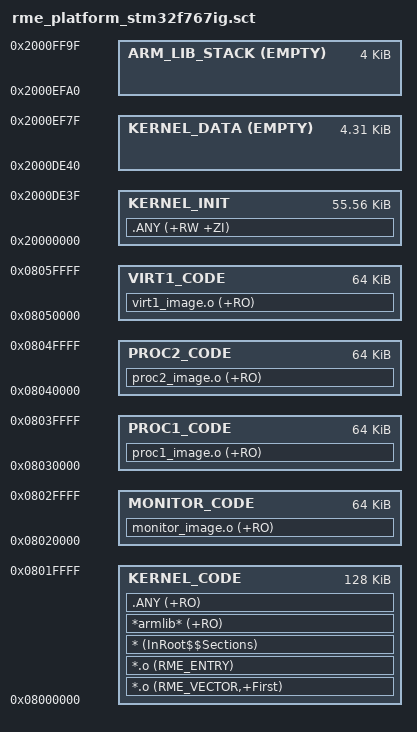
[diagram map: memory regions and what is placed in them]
;******************************************************************************
;Filename    : rme_platform_stm32f767ig.sct
;Author      : The RVM project generator.
;Date        : 26/09/2024 10:23:17
;Licence     : Unlicense; see COPYING for details.
;Description : The scatter file for ARMv7-M layout. This file is intended
;              to be used with STM32F767IG.
;******************************************************************************

;Kernel ***********************************************************************
KERNEL 0x8000000 0x20000
{
    ;Kernel code segment
    KERNEL_CODE 0x8000000 0x20000
    {
        ;The vector table
        *.o                            (RME_VECTOR,+First)
        ;The entry
        *.o                            (RME_ENTRY)
        ;The lib code copying code
        *                              (InRoot$$Sections)
        ;The ARM C library code - all of them is here
        *armlib*                       (+RO)
        ;The kernel code section
        .ANY                           (+RO)
    }

    ;Statically allocated kernel data segment
    KERNEL_INIT 0x20000000 0xDE40
    {
        .ANY                           (+RW +ZI)
    }

    ;Dynamically allocated kernel data segment
    KERNEL_DATA 0x2000DE40 EMPTY 0x1140
    {

    }

    ;Kernel stack segment - required by armlib
    ARM_LIB_STACK 0x2000EFA0 EMPTY 0x1000
    {

    }
}
;End Kernel *******************************************************************

;Monitor **********************************************************************
MONITOR 0x8020000 0x10000
{
    ;Monitor image
    MONITOR_CODE 0x8020000 0x10000
    {
        monitor_image.o                    (+RO)
    }
}
;End Monitor ******************************************************************

;Process **********************************************************************
PROC1 0x8030000 0x10000
{
    ;Process image
    PROC1_CODE 0x8030000 0x10000
    {
        proc1_image.o                   (+RO)
    }
}
;End Process ******************************************************************

;Process **********************************************************************
PROC2 0x8040000 0x10000
{
    ;Process image
    PROC2_CODE 0x8040000 0x10000
    {
        proc2_image.o                   (+RO)
    }
}
;End Process ******************************************************************

;Process **********************************************************************
VIRT1 0x8050000 0x10000
{
    ;Process image
    VIRT1_CODE 0x8050000 0x10000
    {
        virt1_image.o                   (+RO)
    }
}
;End Process ******************************************************************

;End Of File ******************************************************************

;Copyright (C) Evo-Devo Instrum. All rights reserved **************************

